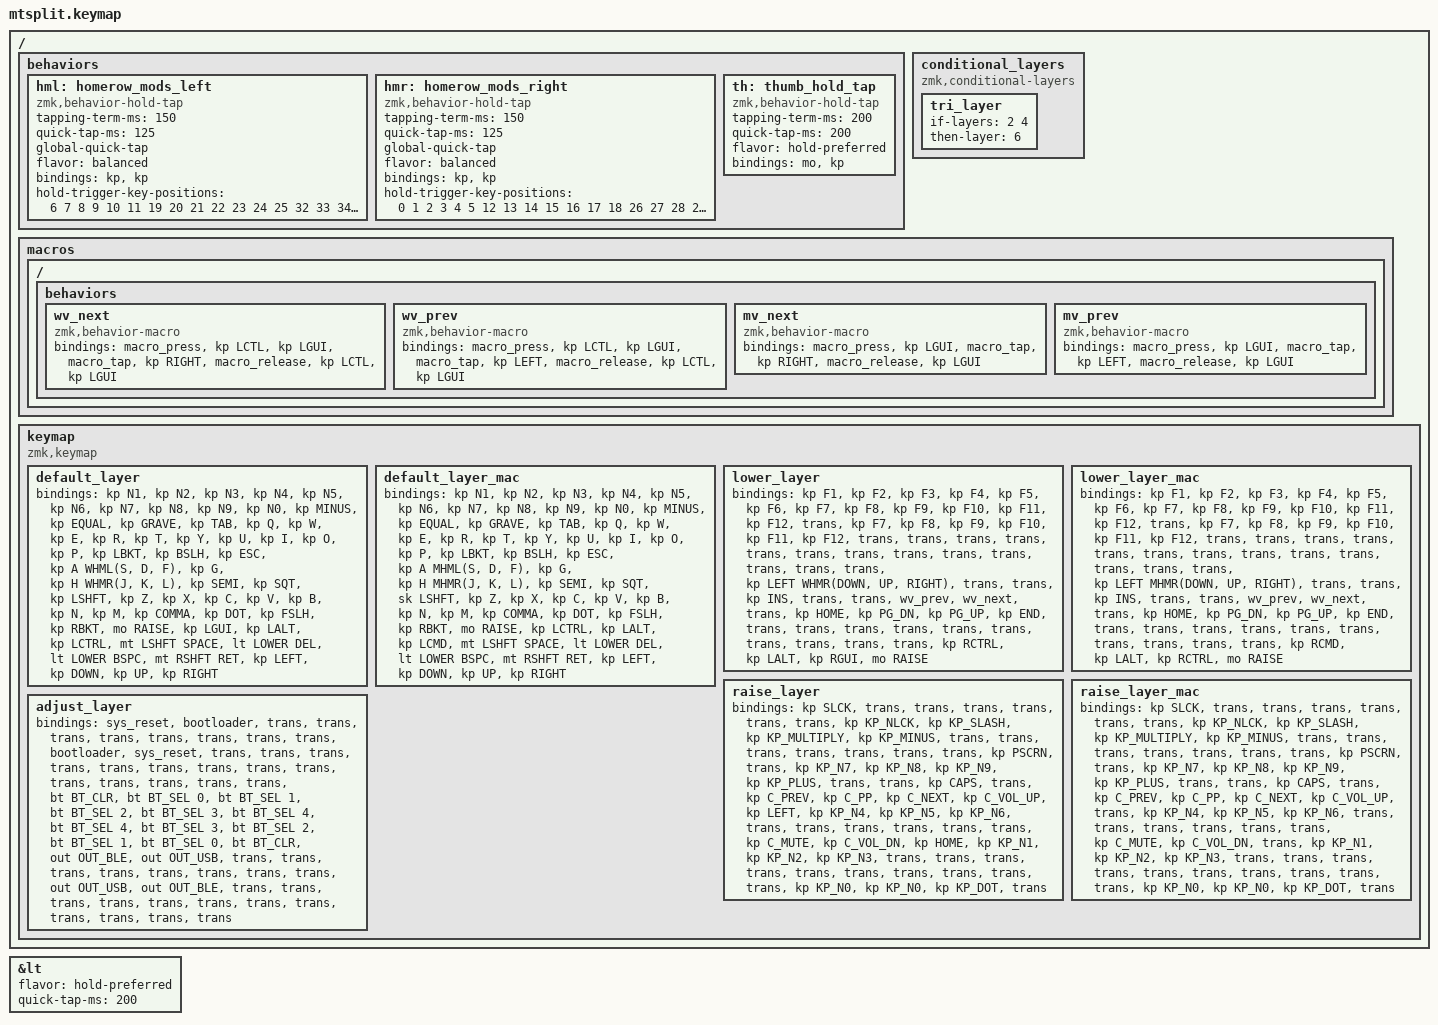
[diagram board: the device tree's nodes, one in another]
/*
 * Copyright (c) 2020 The ZMK Contributors
 *
 * SPDX-License-Identifier: MIT
 */

#include <behaviors.dtsi>
#include <dt-bindings/zmk/keys.h>
#include <dt-bindings/zmk/bt.h>
#include <dt-bindings/zmk/outputs.h>

#define DEFAULT     0
#define DEFAULT_MAC 1
#define LOWER       2
#define LOWER_MAC   3
#define RAISE       4
#define RAISE_MAC   5
#define ADJUST      6

#define WHML(s, d ,f) &hml LGUI s   &hml LALT d     &hml LCTRL f
#define WHMR(j, k, l) &hmr RCTRL j  &hmr LALT k     &hmr RCMD l

#define MHML(s, d, f) &hml LCTRL s  &hml LALT d     &hml LGUI f
#define MHMR(j, k, l) &hmr RCMD j   &hmr LALT k     &hmr RCTRL l


&lt {
    flavor = "hold-preferred";
    quick-tap-ms = <200>;
};

/ {
        behaviors {
            hml: homerow_mods_left {
                compatible = "zmk,behavior-hold-tap";
                #binding-cells = <2>;
                tapping-term-ms = <150>;
                quick-tap-ms = <125>;
                global-quick-tap;
                flavor = "balanced";
                bindings = <&kp>, <&kp>;
                hold-trigger-key-positions = <6 7 8 9 10 11     19 20 21 22 23 24 25    32 33 34 35 36 37   44 45 46 47 48 49   50 51 52 53 54 55 56 57 58 59 60 61>;
            };
            hmr: homerow_mods_right {
                compatible = "zmk,behavior-hold-tap";
                #binding-cells = <2>;
                tapping-term-ms = <150>;
                quick-tap-ms = <125>;
                global-quick-tap;
                flavor = "balanced";
                bindings = <&kp>, <&kp>;
                hold-trigger-key-positions = <0 1 2 3 4 5    12 13 14 15 16 17 18   26 27 28 29 30 31   38 39 40 41 42 43   50 51 52 53 54 55 56 57 58 59 60 61>;
            };
            th: thumb_hold_tap {
                compatible = "zmk,behavior-hold-tap";
                #binding-cells = <2>;
                tapping-term-ms = <200>;
                quick-tap-ms = <200>;
                flavor = "hold-preferred";
                bindings = <&mo>, <&kp>;
            };
        };

        conditional_layers {
            compatible = "zmk,conditional-layers";
            tri_layer {
                if-layers = <2 4>;
                then-layer = <6>;
            };
        };

        macros {
            ZMK_MACRO(wv_next, bindings = <&macro_press &kp LCTL &kp LGUI>, <&macro_tap &kp RIGHT>, <&macro_release &kp LCTL &kp LGUI>;)
            ZMK_MACRO(wv_prev, bindings = <&macro_press &kp LCTL &kp LGUI>, <&macro_tap &kp LEFT>, <&macro_release &kp LCTL &kp LGUI>;)
            ZMK_MACRO(mv_next, bindings = <&macro_press &kp LGUI>, <&macro_tap &kp RIGHT>, <&macro_release &kp LGUI>;)
            ZMK_MACRO(mv_prev, bindings = <&macro_press &kp LGUI>, <&macro_tap &kp LEFT>, <&macro_release &kp LGUI>;)
        };

        keymap {
                compatible = "zmk,keymap";

// -----------------------------------------------------------------------------------------
                default_layer {
                    bindings = <
            &kp N1    &kp N2    &kp N3      &kp N4      &kp N5      &kp N6                                              &kp N7          &kp N8      &kp N9      &kp N0  &kp MINUS   &kp EQUAL
&kp GRAVE   &kp TAB   &kp Q     &kp W       &kp E       &kp R       &kp T                                               &kp Y           &kp U       &kp I       &kp O   &kp P       &kp LBKT    &kp BSLH
            &kp ESC   &kp A     WHML(S,     D,          F)          &kp G                                               &kp H           WHMR(J,     K,          L)      &kp SEMI    &kp SQT
            &kp LSHFT &kp Z     &kp X       &kp C       &kp V       &kp B                                               &kp N           &kp M       &kp COMMA   &kp DOT &kp FSLH    &kp RBKT
                      &mo RAISE &kp LGUI    &kp LALT    &kp LCTRL   &mt LSHFT SPACE &lt LOWER DEL       &lt LOWER BSPC  &mt RSHFT RET   &kp LEFT    &kp DOWN    &kp UP  &kp RIGHT
                        >;
                };

// -----------------------------------------------------------------------------------------
                default_layer_mac {
                    bindings = <
            &kp N1    &kp N2    &kp N3      &kp N4      &kp N5      &kp N6                                              &kp N7          &kp N8      &kp N9      &kp N0  &kp MINUS   &kp EQUAL
&kp GRAVE   &kp TAB   &kp Q     &kp W       &kp E       &kp R       &kp T                                               &kp Y           &kp U       &kp I       &kp O   &kp P       &kp LBKT    &kp BSLH
            &kp ESC   &kp A     MHML(S,     D,          F)          &kp G                                               &kp H           MHMR(J,     K,          L)      &kp SEMI    &kp SQT
            &sk LSHFT &kp Z     &kp X       &kp C       &kp V       &kp B                                               &kp N           &kp M       &kp COMMA   &kp DOT &kp FSLH    &kp RBKT
                      &mo RAISE &kp LCTRL   &kp LALT    &kp LCMD    &mt LSHFT SPACE  &lt LOWER DEL      &lt LOWER BSPC  &mt RSHFT RET   &kp LEFT    &kp DOWN    &kp UP  &kp RIGHT
                        >;
                };

// -----------------------------------------------------------------------------------------
                lower_layer {
                    bindings = <
            &kp F1  &kp F2    &kp F3    &kp F4      &kp F5      &kp F6                                              &kp F7          &kp F8      &kp F9      &kp F10     &kp F11     &kp F12
&trans      &kp F7  &kp F8    &kp F9    &kp F10     &kp F11     &kp F12                                             &trans          &trans      &trans      &trans      &trans      &trans      &trans 
            &trans  &trans    &trans    &trans      &trans      &trans                                              &kp LEFT        WHMR(DOWN,  UP,         RIGHT)      &trans      &trans
            &kp INS &trans    &trans    &wv_prev    &wv_next    &trans                                              &kp HOME        &kp PG_DN   &kp PG_UP   &kp END     &trans      &trans
                    &trans    &trans    &trans      &trans      &trans      &trans                        &trans    &trans          &kp RCTRL   &kp LALT    &kp RGUI    &mo RAISE
                        >;
                };

// -----------------------------------------------------------------------------------------
                lower_layer_mac {
                    bindings = <
            &kp F1  &kp F2    &kp F3    &kp F4      &kp F5      &kp F6                                              &kp F7          &kp F8      &kp F9      &kp F10     &kp F11     &kp F12
&trans      &kp F7  &kp F8    &kp F9    &kp F10     &kp F11     &kp F12                                             &trans          &trans      &trans      &trans      &trans      &trans      &trans 
            &trans  &trans    &trans    &trans      &trans      &trans                                              &kp LEFT        MHMR(DOWN,  UP,         RIGHT)      &trans      &trans
            &kp INS &trans    &trans    &wv_prev    &wv_next    &trans                                              &kp HOME        &kp PG_DN   &kp PG_UP   &kp END     &trans      &trans
                    &trans    &trans    &trans      &trans      &trans      &trans                        &trans    &trans          &kp RCMD    &kp LALT    &kp RCTRL   &mo RAISE
                        >;
                };

// -----------------------------------------------------------------------------------------
                raise_layer {
                    bindings = <
            &kp SLCK    &trans    &trans        &trans      &trans      &trans                                              &trans          &kp KP_NLCK &kp KP_SLASH    &kp KP_MULTIPLY &kp KP_MINUS    &trans
&trans      &trans      &trans    &trans        &trans      &trans      &kp PSCRN                                           &trans          &kp KP_N7   &kp KP_N8       &kp KP_N9       &kp KP_PLUS     &trans      &trans 
            &kp CAPS    &trans    &kp C_PREV    &kp C_PP    &kp C_NEXT  &kp C_VOL_UP                                        &kp LEFT        &kp KP_N4   &kp KP_N5       &kp KP_N6       &trans          &trans
            &trans      &trans    &trans        &trans      &kp C_MUTE  &kp C_VOL_DN                                        &kp HOME        &kp KP_N1   &kp KP_N2       &kp KP_N3       &trans          &trans
                        &trans    &trans        &trans      &trans      &trans      &trans                        &trans    &trans          &kp KP_N0   &kp KP_N0       &kp KP_DOT      &trans
                        >;
                };

// -----------------------------------------------------------------------------------------
                raise_layer_mac {
                    bindings = <
            &kp SLCK    &trans    &trans        &trans      &trans      &trans                                              &trans          &kp KP_NLCK &kp KP_SLASH    &kp KP_MULTIPLY &kp KP_MINUS    &trans
&trans      &trans      &trans    &trans        &trans      &trans      &kp PSCRN                                           &trans          &kp KP_N7   &kp KP_N8       &kp KP_N9       &kp KP_PLUS     &trans      &trans 
            &kp CAPS    &trans    &kp C_PREV    &kp C_PP    &kp C_NEXT  &kp C_VOL_UP                                        &trans          &kp KP_N4   &kp KP_N5       &kp KP_N6       &trans          &trans
            &trans      &trans    &trans        &trans      &kp C_MUTE  &kp C_VOL_DN                                        &trans          &kp KP_N1   &kp KP_N2       &kp KP_N3       &trans          &trans
                        &trans    &trans        &trans      &trans      &trans      &trans                        &trans    &trans          &kp KP_N0   &kp KP_N0       &kp KP_DOT      &trans
                        >;
                };

// -----------------------------------------------------------------------------------------
                adjust_layer {
                    bindings = <
        &sys_reset      &bootloader    &trans          &trans          &trans          &trans                               &trans          &trans          &trans          &trans          &bootloader     &sys_reset
&trans  &trans          &trans         &trans          &trans          &trans          &trans                               &trans          &trans          &trans          &trans          &trans          &trans      &trans
        &bt BT_CLR      &bt BT_SEL 0   &bt BT_SEL 1    &bt BT_SEL 2    &bt BT_SEL 3    &bt BT_SEL 4                         &bt BT_SEL 4    &bt BT_SEL 3    &bt BT_SEL 2    &bt BT_SEL 1    &bt BT_SEL 0    &bt BT_CLR
        &out OUT_BLE    &out OUT_USB   &trans          &trans          &trans          &trans                               &trans          &trans          &trans          &trans          &out OUT_USB    &out OUT_BLE
                        &trans         &trans          &trans          &trans          &trans       &trans      &trans      &trans          &trans          &trans          &trans          &trans
                        >;
                };
        };
};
